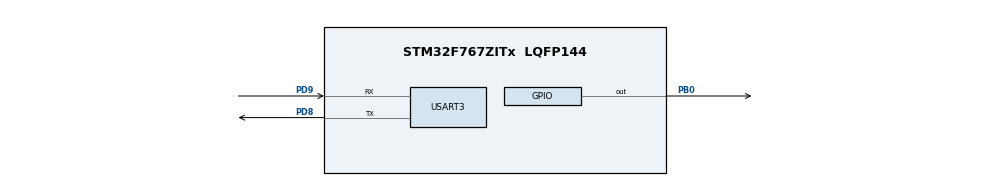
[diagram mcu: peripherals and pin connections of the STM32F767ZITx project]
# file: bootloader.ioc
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Mcu.Family=STM32F7
Mcu.Name=STM32F767ZITx
Mcu.Package=LQFP144
NVIC.PriorityGroup=NVIC_PRIORITYGROUP_4
PB0.Signal=GPIO_Output
PD8.Mode=Asynchronous
PD8.Signal=USART3_TX
PD9.Mode=Asynchronous
PD9.Signal=USART3_RX
ProjectManager.HeapSize=0x200
ProjectManager.StackSize=0x400
ProjectManager.TargetToolchain=STM32CubeIDE
RCC.HSE_VALUE=25000000
RCC.HSI_VALUE=16000000
RCC.LSE_VALUE=32768
RCC.USBFreq_Value=96000000
RCC.VCOOutputFreq_Value=192000000
USART3.VirtualMode-Asynchronous=VM_ASYNC
board=custom

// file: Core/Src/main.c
/* USER CODE BEGIN Header */
/**
  ******************************************************************************
  * @file           : main.c
  * @brief          : Main program body
  ******************************************************************************
  * @attention
  *
  * Copyright (c) 2025 STMicroelectronics.
  * All rights reserved.
  *
  * This software is licensed under terms that can be found in the LICENSE file
  * in the root directory of this software component.
  * If no LICENSE file comes with this software, it is provided AS-IS.
  *
  ******************************************************************************
  */
/* USER CODE END Header */
#include "main.h"
#include "usart.h"
#include "gpio.h"

/* USER CODE BEGIN Includes */
#include <stdio.h>
/* USER CODE END Includes */

/* USER CODE BEGIN PM */
#define MAJOR 0   // BL Major version Number
#define MINOR 1   // BL Minor version Number
/* USER CODE END PM */

/* USER CODE BEGIN PV */
const uint8_t BL_Version[2] = { MAJOR, MINOR };
/* USER CODE END PV */

void SystemClock_Config(void);
/* USER CODE BEGIN PFP */
static void goto_application( void );
/* USER CODE END PFP */

int main(void)
{

  /* MCU Configuration--------------------------------------------------------*/

  /* Reset of all peripherals, Initializes the Flash interface and the Systick. */
  HAL_Init();

  /* Configure the system clock */
  SystemClock_Config();

  /* Initialize all configured peripherals */
  MX_GPIO_Init();
  MX_USART3_UART_Init();
  /* USER CODE BEGIN 2 */
  printf("Starting Bootloader (%d.%d)\r\n", BL_Version[0], BL_Version[1]);
  HAL_GPIO_WritePin(GPIOB, GPIO_PIN_0, GPIO_PIN_SET );    //Green LED ON
  HAL_Delay(2000);
  goto_application();
  /* USER CODE END 2 */

  /* Infinite loop */
  while (1)
  {

  }
}

void SystemClock_Config(void)
{
  RCC_OscInitTypeDef RCC_OscInitStruct = {0};
  RCC_ClkInitTypeDef RCC_ClkInitStruct = {0};

  /** Configure the main internal regulator output voltage
  */
  __HAL_RCC_PWR_CLK_ENABLE();
  __HAL_PWR_VOLTAGESCALING_CONFIG(PWR_REGULATOR_VOLTAGE_SCALE3);

  /** Initializes the RCC Oscillators according to the specified parameters
  * in the RCC_OscInitTypeDef structure.
  */
  RCC_OscInitStruct.OscillatorType = RCC_OSCILLATORTYPE_HSI;
  RCC_OscInitStruct.HSIState = RCC_HSI_ON;
  RCC_OscInitStruct.HSICalibrationValue = RCC_HSICALIBRATION_DEFAULT;
  RCC_OscInitStruct.PLL.PLLState = RCC_PLL_NONE;
  if (HAL_RCC_OscConfig(&RCC_OscInitStruct) != HAL_OK)
  {
    Error_Handler();
  }

  /** Initializes the CPU, AHB and APB buses clocks
  */
  RCC_ClkInitStruct.ClockType = RCC_CLOCKTYPE_HCLK|RCC_CLOCKTYPE_SYSCLK
                              |RCC_CLOCKTYPE_PCLK1|RCC_CLOCKTYPE_PCLK2;
  RCC_ClkInitStruct.SYSCLKSource = RCC_SYSCLKSOURCE_HSI;
  RCC_ClkInitStruct.AHBCLKDivider = RCC_SYSCLK_DIV1;
  RCC_ClkInitStruct.APB1CLKDivider = RCC_HCLK_DIV1;
  RCC_ClkInitStruct.APB2CLKDivider = RCC_HCLK_DIV1;

  if (HAL_RCC_ClockConfig(&RCC_ClkInitStruct, FLASH_LATENCY_0) != HAL_OK)
  {
    Error_Handler();
  }
}

/* USER CODE BEGIN 4 */
/**
  * @brief Jump to application from the Bootloader
  * @retval None
  */
static void goto_application(void)
{
  printf("Gonna Jump to Application\r\n");
  void (*app_reset_handler)(void) = (void*)(*((volatile uint32_t*) (0x08040000 + 4U)));
  //__set_MSP(*(volatile uint32_t*) 0x08040000);
  // Turn OFF the Green Led to tell the user that Bootloader is not running
  HAL_GPIO_WritePin(GPIOB, GPIO_PIN_0, GPIO_PIN_RESET );    //Green LED OFF

  /* Reset the Clock */
  HAL_RCC_DeInit();
  HAL_DeInit();
  __set_MSP(*(volatile uint32_t*) 0x08040000);
  SysTick->CTRL = 0;
  SysTick->LOAD = 0;
  SysTick->VAL = 0;
  /* Jump to application */
  app_reset_handler();    //call the app reset handler
}

/**
  * @brief Print the characters to UART (printf).
  * @retval int
  */
#ifdef __GNUC__
  /* With GCC, small printf (option LD Linker->Libraries->Small printf
     set to 'Yes') calls __io_putchar() */
int __io_putchar(int ch)
#else
int fputc(int ch, FILE *f)
#endif /* __GNUC__ */
{
  /* Place your implementation of fputc here */
  /* e.g. write a character to the UART3 and Loop until the end of transmission */
  HAL_UART_Transmit(&huart3, (uint8_t *)&ch, 1, HAL_MAX_DELAY);
  return ch;
}
/* USER CODE END 4 */

void Error_Handler(void)
{
  __disable_irq();
  while (1)
  {
  }
}
